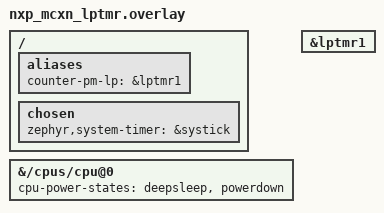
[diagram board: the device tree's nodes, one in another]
/*
 * SPDX-FileCopyrightText: Copyright 2026 NXP
 * SPDX-License-Identifier: Apache-2.0
 */

/ {
	aliases {
		counter-pm-lp = &lptmr1;
	};

	chosen {
		zephyr,system-timer = &systick;
	};
};

&{/cpus/cpu@0} {
	cpu-power-states = <&deepsleep &powerdown>;
};

&lptmr1 {
	status = "okay";
};
